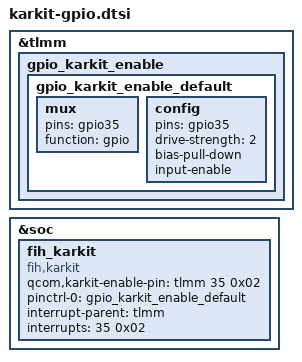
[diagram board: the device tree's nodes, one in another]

&tlmm {
	gpio_karkit_enable {
		gpio_karkit_enable_default: gpio_karkit_enable_default {
			mux {
				pins = "gpio35";
				function = "gpio";
			};
			config {
				pins = "gpio35";
        drive-strength = <2>;
        bias-pull-down;//bias-disable;
        input-enable;
			};
		};
	};
};

&soc {
		fih_karkit {
			compatible = "fih,karkit";
			status = "ok";
			qcom,karkit-enable-pin = <&tlmm 35 0x02>;
			pinctrl-names = "default";
			pinctrl-0 = <&gpio_karkit_enable_default>;
			interrupt-parent = <&tlmm>;
      interrupts = <35 0x02>;
		};
};

